# CY8C5888LTI_LP097 register map
File version: 0.1
CY8C58LP
Registers are 8-bit, read-write, no defined reset value unless marked. A register's access mark holds for its fields unless they carry their own. Offsets are from the block's base; lines under a group give offsets from that group; [hi:lo] are bit positions; {n}, {i} and the like mark numbered series; 'fields as' and 'values as' point back to an identical list; <NAME> marks a mode.

## Memory map
0x00000000 UpDown
0x00000000 ADC_SAR_SEQ_SAR — SAR ADC
0x00000000 ROSSerial_UART — USBFS
0x00000000 QuadDec_1
0x00000000 QuadDec_1_Cnt16
0x00000000 PWM_1
0x00000000 CapSense
0x00000000 CapSense_IdacCH0
0x00000000 CapSense_CompCH0
0x40006578 Stepper_Control

## Stepper_Control
Base 0x40006578
0x00 Stepper_Control_CONTROL_REG

## UpDown
Base 0x00000000
0x40006508 UpDown_COUNTER 32-bit — UDB.A0 - Current Counter Value
0x40006528 UpDown_PERIOD 32-bit — UDB.D0 - Assigned Period
0x40006538 UpDown_COMPARE 32-bit — UDB.D1 - Assigned Compare Value
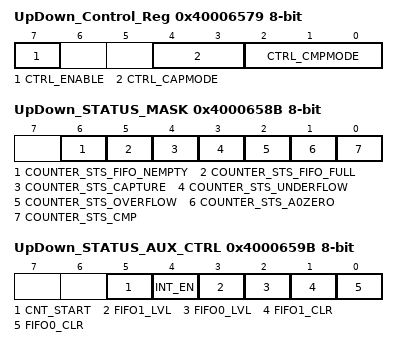
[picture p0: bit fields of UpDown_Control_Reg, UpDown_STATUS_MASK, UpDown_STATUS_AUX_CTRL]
0x40006579 UpDown_Control_Reg — UDB Control Register - Assigned Control Register Value
  [7] CTRL_ENABLE — Enable Counter
  [4:3] CTRL_CAPMODE — Capture mode
  [2:0] CTRL_CMPMODE — Compare mode
0x4000658B UpDown_STATUS_MASK — UDB Status bits Interrupt Mask Enable Register
  [6] COUNTER_STS_FIFO_NEMPTY — FIFO Not Empty Status
  [5] COUNTER_STS_FIFO_FULL — FIFO Full Status
  [4] COUNTER_STS_CAPTURE — Capture Status
  [3] COUNTER_STS_UNDERFLOW — Underflow status
  [2] COUNTER_STS_OVERFLOW — Overflow status
  [1] COUNTER_STS_A0ZERO — A0 Zero ouput status
  [0] COUNTER_STS_CMP — Compare output status
0x4000659B UpDown_STATUS_AUX_CTRL — UDB Auxilliary Control Register
  [5] CNT_START — FIFO0 clear
    0=E_CNT_START0 (Disable counter); 1=E_CNT_START1 (Enable counter)
  [4] INT_EN
    0=E_INT_EN0 (Interrupt disabled); 1=E_INT_EN1 (Interrupt enabled)
  [3] FIFO1_LVL — FIFO level
    0=E_FIFO_LVL_0 (FIFO LVL: input mode: FIFO not full; output mode: FIFO not empty); 1=E_FIFO_LVL_1 (FIFO LVL: input mode: FIFO at least 1/2 empty; output mode: FIFO at least 1/2 full)
  [2] FIFO0_LVL — FIFO level
    values as FIFO1_LVL
  [1] FIFO1_CLR — FIFO1 clear
    0=E_FIFO_CLR_0 (Normal FIFO operation); 1=E_FIFO_CLR_1 (Clear FIFO state)
  [0] FIFO0_CLR — FIFO0 clear
    values as FIFO1_CLR

## ADC_SAR_SEQ_SAR — SAR ADC
Base 0x00000000
0x40004614 SAR_TR0 — SAR trim register
{0x40005900+i} SAR_CSR{i} (i=0..6) — SAR status and control register {i}
0x40005B20 SAR_SW0 — SAR Analog Routing Register 0
{0x40005B20+i} SAR_SW{i} (i=2..4) — SAR Analog Routing Register {i}
0x40005B26 SAR_SW6 — SAR Analog Routing Register 6
0x40005B27 SAR_CLK — SAR Clock Selection Register
0x40005BA0 SAR_WRK 16-bit — SAR working register

## ROSSerial_UART — USBFS
Base 0x00000000
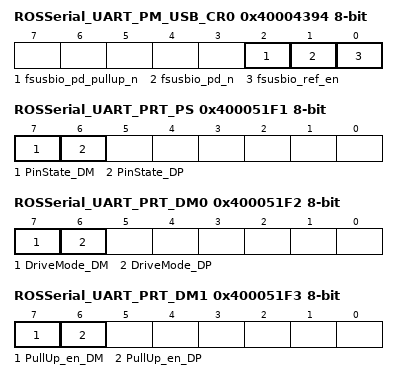
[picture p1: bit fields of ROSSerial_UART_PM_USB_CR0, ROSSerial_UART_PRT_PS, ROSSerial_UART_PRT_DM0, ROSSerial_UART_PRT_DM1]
0x40004394 ROSSerial_UART_PM_USB_CR0 — USB Power Mode Control Register 0
  [2] fsusbio_pd_pullup_n, [1] fsusbio_pd_n, [0] fsusbio_ref_en
0x400043A5 ROSSerial_UART_PM_ACT_CFG — Active Power Mode Configuration Register
0x400043B5 ROSSerial_UART_PM_STBY_CFG — Standby Power Mode Configuration Register
0x400051F1 ROSSerial_UART_PRT_PS — Port Pin State Register
  [7] PinState_DM ro, [6] PinState_DP ro
0x400051F2 ROSSerial_UART_PRT_DM0 — Port Drive Mode Register
  [7] DriveMode_DM, [6] DriveMode_DP
0x400051F3 ROSSerial_UART_PRT_DM1 — Port Drive Mode Register
  [7] PullUp_en_DM, [6] PullUp_en_DP
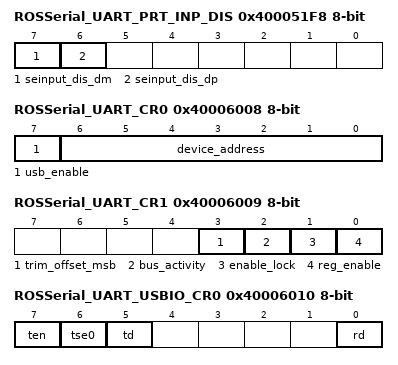
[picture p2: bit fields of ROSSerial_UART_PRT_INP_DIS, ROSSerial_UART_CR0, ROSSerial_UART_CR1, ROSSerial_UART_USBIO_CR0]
0x400051F8 ROSSerial_UART_PRT_INP_DIS — Input buffer disable override
  [7] seinput_dis_dm, [6] seinput_dis_dp
0x40006000 ROSSerial_UART_EP0_DR0 — bmRequestType
0x40006001 ROSSerial_UART_EP0_DR1 — bRequest
0x40006002 ROSSerial_UART_EP0_DR2 — wValueLo
0x40006003 ROSSerial_UART_EP0_DR3 — wValueHi
0x40006004 ROSSerial_UART_EP0_DR4 — wIndexLo
0x40006005 ROSSerial_UART_EP0_DR5 — wIndexHi
0x40006006 ROSSerial_UART_EP0_DR6 — lengthLo
0x40006007 ROSSerial_UART_EP0_DR7 — lengthHi
0x40006008 ROSSerial_UART_CR0 — USB Control Register 0
  [7] usb_enable, [6:0] device_address ro
0x40006009 ROSSerial_UART_CR1 — USB Control Register 1
  [3] trim_offset_msb, [2] bus_activity, [1] enable_lock, [0] reg_enable
{0x40005FFE+0x10*i} ROSSerial_UART_SIE_EP{i}_CR0 (i=1..8) — The Endpoint{i} Control Register
0x40006010 ROSSerial_UART_USBIO_CR0 — USBIO Control Register 0
  [7] ten, [6] tse0, [5] td, [0] rd ro
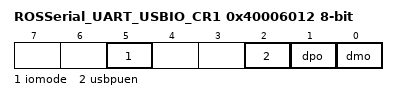
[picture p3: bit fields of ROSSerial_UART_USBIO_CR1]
0x40006012 ROSSerial_UART_USBIO_CR1 — USBIO Control Register 1
  [5] iomode, [2] usbpuen, [1] dpo ro, [0] dmo ro
0x4000608C ROSSerial_UART_BUF_SIZE — Dedicated Endpoint Buffer Size Register
0x4000608E ROSSerial_UART_EP_ACTIVE — Endpoint Active Indication Register
0x4000608F ROSSerial_UART_EP_TYPE — Endpoint Type (IN/OUT) Indication
0x4000609D ROSSerial_UART_USB_CLK_EN — USB Block Clock Enable Register
